# AT32F423 register map
Vendor: Keil; Series: AT32F423; File version: 1.0
CPU: CM4 r0p1, little endian, no MPU, FPU, 4 interrupt priority bits
Registers are 32-bit, read-write, reset 0x0 unless marked. A register's access mark holds for its fields unless they carry their own. Offsets are from the block's base; [hi:lo] are bit positions; lines under a group give offsets from that group; {n}, {i} and the like mark numbered series; 'fields as' and 'values as' point back to an identical list.

## ADC1 — Analog to digital converter
Base 0x40012000
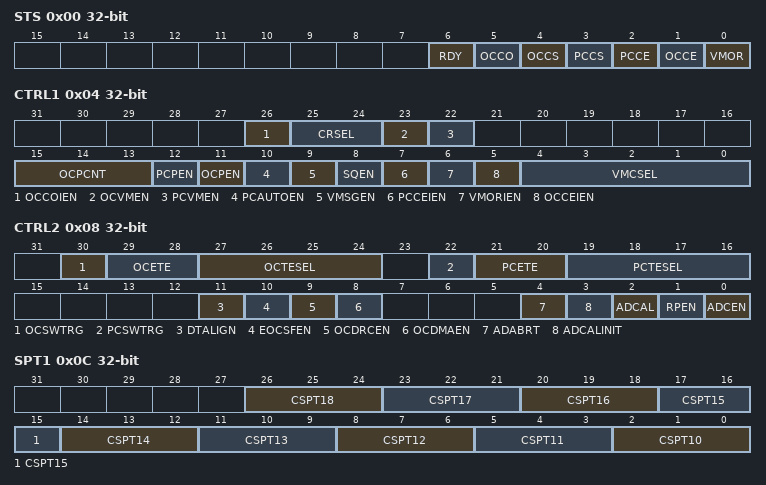
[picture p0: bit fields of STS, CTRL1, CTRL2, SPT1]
0x00 STS — status register
  [6] RDY ro — ADC ready to conversion flag
  [5] OCCO write-0-clears — Ordinary channel conversion overflow flag
  [4] OCCS write-0-clears — Ordinary channel conversion start flag
    on read: 0=Idle (No channel conversion started); 1=Started (Channel conversion has started) | on write: 0=Clear flag
  [3] PCCS write-0-clears — Preempted channel conversion start flag
    values as OCCS
  [2] PCCE write-0-clears — Preempted channels conversion end flag
    on read: 0=NotComplete (Conversion is not complete); 1=Complete (Conversion is complete) | on write: 0=Clear flag
  [1] OCCE write-0-clears — Ordinary channels conversion end flag
    values as PCCE
  [0] VMOR write-0-clears — Voltage monitoring out of range flag
    on read: 0=InRange (Voltage is within the value programmed); 1=OutOfRange (Voltage is outside the value programmed) | on write: 0=Clear flag
0x04 CTRL1 — control register 1
  [26] OCCOIEN — Ordinary channel conversion overflow interrupt enable
  [25:24] CRSEL — Conversion resolution select
  [23] OCVMEN — Voltage monitoring enable on ordinary channels
    on read: 0=Disabled (Voltage monitoring is disabled); 1=Enabled (Voltage monitoring is enabled) | on write: 0=Disable (Voltage monitoring disable); 1=Enable (Voltage monitoring enable)
  [22] PCVMEN — Voltage monitoring enable on preempted channels
    values as OCVMEN
  [15:13] OCPCNT — Partitioned mode conversion count of ordinary channels
  [12] PCPEN — Partitioned mode enable on preempted channels
    on read: 0=Disabled (Partitioned mode on channels is disabled); 1=Enabled (Partitioned mode on channels is enabled) | on write: 0=Disable (Partitioned mode on channels disable); 1=Enable (Partitioned mode on channels enable)
  [11] OCPEN — Partitioned mode enable on ordinary channels
    values as PCPEN
  [10] PCAUTOEN — Preempted group automatic conversion enable after ordinary group
    on read: 0=Disabled (Preempted group automatic conversion is disabled); 1=Enabled (Preempted group automatic conversion is enabled) | on write: 0=Disable (Preempted group automatic conversion disable); 1=Enable (Preempted group automatic conversion enable)
  [9] VMSGEN — Voltage monitoring enable on a single channel
    0=All (Voltage monitoring enabled on all channels); 1=Single (Voltage monitoring enabled a single channel)
  [8] SQEN — Sequence mode enable
    on read: 0=Disabled (Sequence mode is disabled); 1=Enabled (Sequence mode is enabled) | on write: 0=Disable (Sequence mode disable); 1=Enable (Sequence mode enable)
  [7] PCCEIEN — Conversion end interrupt enable for preempted channels
    on read: 0=Disabled (Channel conversion end interrupt is disabled); 1=Enabled (Channel conversion end interrupt is enabled) | on write: 0=Disable (Channel conversion end interrupt disable); 1=Enable (Channel conversion end interrupt enable)
  [6] VMORIEN — Voltage monitoring out of range interrupt enable
    on read: 0=Disabled (Voltage monitoring out of range interrupt is disabled); 1=Enabled (Voltage monitoring out of range interrupt is enabled) | on write: 0=Disable (Voltage monitoring out of range interrupt disable); 1=Enable (Voltage monitoring out of range interrupt enable)
  [5] OCCEIEN — Ordinary channel conversion end interrupt enable
    values as PCCEIEN
  [4:0] VMCSEL range 0..17 — Voltage monitoring channel select
0x08 CTRL2 — control register 2
  [30] OCSWTRG — Ordinary channel software conversion trigger
    0=NotTriggered (Conversion of ordinary channels not triggered); 1=Triggered (Conversion of ordinary channels triggered)
  [29:28] OCETE — Ordinary channel external trigger edge select
  [27:24] OCTESEL — trigger event select for ordinary channels conversion
  [22] PCSWTRG — Preempted channel software conversion trigger
    0=NotTriggered (Conversion of preempted channels not triggered); 1=Triggered (Conversion of preempted channels triggered)
  [21:20] PCETE — Preempted channel external trigger edge select
  [19:16] PCTESEL — trigger event select for preempted channels conversion
  [11] DTALIGN — Data alignment
    0=Right alignment; 1=Left alignment
  [10] EOCSFEN — Each ordinary channel conversion set OCCE flag enable
  [9] OCDRCEN — Ordinary channel DMA request continuation enable for independent mode
  [8] OCDMAEN — Ordinary channel DMA transfer enable for independent mode
  [4] ADABRT — ADC conversion abort
  [3] ADCALINIT — Initialize A/D calibration
    on read: 0=Completed (Initialization completed); 1=InProgress (Initialization is in process) | on write: 1=Init (Enable initialization)
  [2] ADCAL — A/D Calibration
    on read: 0=Completed (Calibration completed); 1=InProgress (Calibration is in process) | on write: 1=Calibrate (Enable calibration)
  [1] RPEN — Repeat mode enable
    on read: 0=Disabled (Repetition mode is disabled); 1=Enabled (Repetition mode is enabled) | on write: 0=Disable (Repetition mode disable); 1=Enable (Repetition mode enable)
  [0] ADCEN — A/D converter enable
    on read: 0=Disabled (ADC is disabled); 1=Enabled (ADC is enabled) | on write: 0=Disable (ADC disable); 1=Enable (ADC enable)
0x0C SPT1 — sample time register 1
  [3n-28:3n-30] CSPT{n} (n=10..18) — Selection sample time of channel ADC_IN{n}
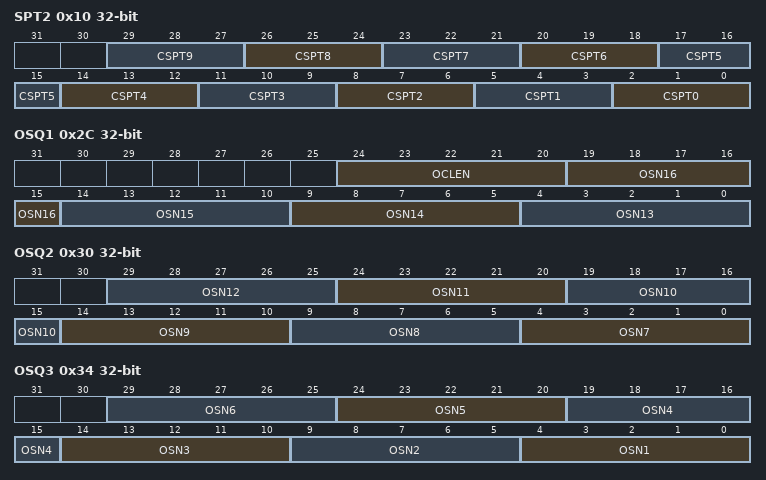
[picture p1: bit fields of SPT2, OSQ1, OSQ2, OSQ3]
0x10 SPT2 — sample time register 2
  [3n+2:3n] CSPT{n} (n=0..9) — Selection sample time of channel ADC_IN{n}
{0x10+4i} PCDTO{i} (i=1..4) — Data offset for Preempted channel {i}
  [11:0] DTO — Data offset for Preempted channel 1
0x24 VMHB reset 0xFFFF — Voltage monitoring high boundary register
  [15:0] VMB — Voltage monitoring high boundary
0x28 VMLB — Voltage monitoring low boundary register
  [15:0] VMB — Voltage monitoring low boundary
0x2C OSQ1 — Ordinary sequence register 1
  [24:20] OCLEN range 0..15 — Ordinary conversion sequence length
  [5n-61:5n-65] OSN{n} (n=13..16) — Number of {n}th conversion in ordinary sequence
    {v}=AdcIn{v} (v=0..17)
0x30 OSQ2 — Ordinary sequence register 2
  [5n-31:5n-35] OSN{n} (n=7..12) — Number of {n}th conversion in ordinary sequence
    {v}=AdcIn{v} (v=0..17)
0x34 OSQ3 — Ordinary sequence register 3
  [5n-1:5n-5] OSN{n} (n=1..6) — Number of {n}th conversion in ordinary sequence
    {v}=AdcIn{v} (v=0..17)
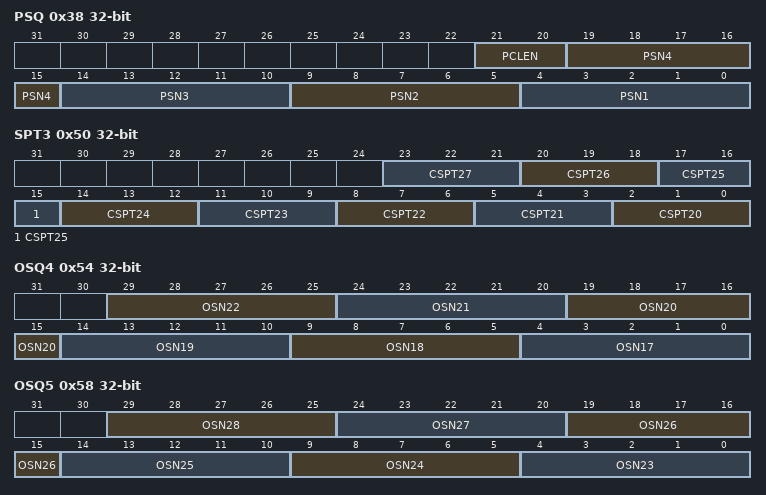
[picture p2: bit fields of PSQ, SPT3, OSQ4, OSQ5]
0x38 PSQ — Preempted sequence register
  [21:20] PCLEN — Preempted conversion sequence length
  [5n-1:5n-5] PSN{n} (n=1..4) range 0..17 — Number of {n} conversion in preempted sequence
{0x38+4i} PDT{i} (i=1..4) ro — Preempted data register {i}
  [15:0] PDT — Preempted data
0x4C ODT ro — Ordinary data register
  [15:0] ODT — Conversion data of ordinary channel
0x50 SPT3 — sample time register 3
  [3n-58:3n-60] CSPT{n} (n=20..27) — Selection sample time of channel ADC_IN{n}
0x54 OSQ4 — Ordinary sequence register 4
  [all] fields
    {v}=AdcIn{v} (v=0..17)
  [29:25] OSN22 — Number of 22th conversion in ordinary sequence
  [24:20] OSN21 — Number of 21th conversion in ordinary sequence
  [19:15] OSN20 — Number of 20th conversion in ordinary sequence
  [14:10] OSN19 — number of 19rd conversion in ordinary sequence
  [9:5] OSN18 — Number of 18nd conversion in ordinary sequence
  [4:0] OSN17 — Number of 17st conversion in ordinary sequence
0x58 OSQ5 — Ordinary sequence register 5
  [all] fields
    {v}=AdcIn{v} (v=0..17)
  [29:25] OSN28 — Number of 28th conversion in ordinary sequence
  [24:20] OSN27 — Number of 27th conversion in ordinary sequence
  [19:15] OSN26 — Number of 26th conversion in ordinary sequence
  [14:10] OSN25 — number of 25rd conversion in ordinary sequence
  [9:5] OSN24 — Number of 24nd conversion in ordinary sequence
  [4:0] OSN23 — Number of 23st conversion in ordinary sequence
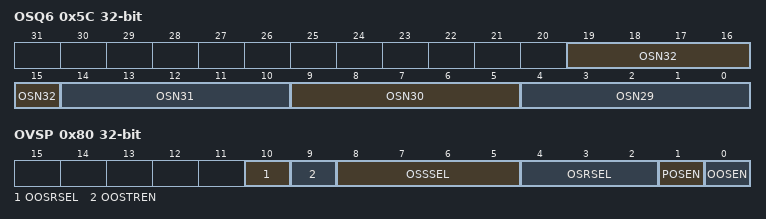
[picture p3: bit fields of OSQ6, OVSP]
0x5C OSQ6 — Ordinary sequence register 6
  [all] fields
    {v}=AdcIn{v} (v=0..17)
  [19:15] OSN32 — Number of 32th conversion in ordinary sequence
  [14:10] OSN31 — number of 31rd conversion in ordinary sequence
  [9:5] OSN30 — Number of 30nd conversion in ordinary sequence
  [4:0] OSN29 — Number of 29st conversion in ordinary sequence
0x80 OVSP — oversampling register
  [10] OOSRSEL — Ordinary oversampling recovery mode select
  [9] OOSTREN — Ordinary oversampling trigger mode enable
  [8:5] OSSSEL — Oversampling shift select
  [4:2] OSRSEL — Oversampling ratio select
  [1] POSEN — Preempted oversampling enable
  [0] OOSEN — Ordinary oversampling enable
0xB4 CALVAL — Calibration value register
  [6:0] CALVAL — A/D Calibration value
